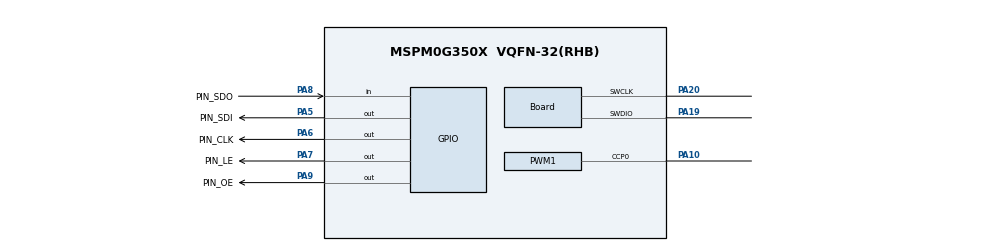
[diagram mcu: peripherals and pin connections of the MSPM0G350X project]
/**
 * @cliArgs --device "MSPM0G350X" --part "Default" --package "VQFN-32(RHB)" --product "mspm0_sdk@2.04.00.06"
 * @versions {"tool":"1.23.0+4000"}
 */

/**
 * Import the modules used in this configuration.
 */
const GPIO   = scripting.addModule("/ti/driverlib/GPIO", {}, false);
const GPIO1  = GPIO.addInstance();
const GPIO2  = GPIO.addInstance();
const GPIO3  = GPIO.addInstance();
const GPIO4  = GPIO.addInstance();
const GPIO5  = GPIO.addInstance();
const PWM    = scripting.addModule("/ti/driverlib/PWM", {}, false);
const PWM1   = PWM.addInstance();
const SYSCTL = scripting.addModule("/ti/driverlib/SYSCTL");

/**
 * Write custom configuration values to the imported modules.
 */
GPIO1.$name                         = "GPIO_SDI";
GPIO1.associatedPins[0].$name       = "PIN_SDI";
GPIO1.associatedPins[0].pin.$assign = "PA5";

const Board                       = scripting.addModule("/ti/driverlib/Board", {}, false);
Board.peripheral.$assign          = "DEBUGSS";
Board.peripheral.swclkPin.$assign = "PA20";
Board.peripheral.swdioPin.$assign = "PA19";

GPIO2.$name                         = "GPIO_CLK";
GPIO2.associatedPins[0].$name       = "PIN_CLK";
GPIO2.associatedPins[0].pin.$assign = "PA6";

GPIO3.$name                         = "GPIO_LE";
GPIO3.associatedPins[0].$name       = "PIN_LE";
GPIO3.associatedPins[0].pin.$assign = "PA7";

GPIO4.$name                         = "GPIO_SDO";
GPIO4.associatedPins[0].$name       = "PIN_SDO";
GPIO4.associatedPins[0].direction   = "INPUT";
GPIO4.associatedPins[0].pin.$assign = "PA8";

GPIO5.$name                         = "GPIO_OE";
GPIO5.associatedPins[0].$name       = "PIN_OE";
GPIO5.associatedPins[0].pin.$assign = "PA9";

PWM1.clockDivider                       = 8;
PWM1.clockPrescale                      = 20;
PWM1.timerCount                         = 2000;
PWM1.timerStartTimer                    = true;
PWM1.interrupts                         = ["LOAD_EVENT"];
PWM1.ccIndex                            = [0];
PWM1.$name                              = "PWM_1";
PWM1.PWM_CHANNEL_0.$name                = "ti_driverlib_pwm_PWMTimerCC0";
PWM1.PWM_CHANNEL_0.ccValue              = 1800;
PWM1.PWM_CHANNEL_0.dutyCycle            = 10;
PWM1.ccp0PinConfig.$name                = "ti_driverlib_gpio_GPIOPinGeneric0";
PWM1.ccp0PinConfig.direction            = scripting.forceWrite("OUTPUT");
PWM1.ccp0PinConfig.hideOutputInversion  = scripting.forceWrite(false);
PWM1.ccp0PinConfig.onlyInternalResistor = scripting.forceWrite(false);
PWM1.ccp0PinConfig.passedPeripheralType = scripting.forceWrite("Digital");
PWM1.peripheral.$assign                 = "TIMA1";
PWM1.peripheral.ccp0Pin.$assign         = "PA10";

SYSCTL.forceDefaultClkConfig = true;
SYSCTL.clockTreeEn           = true;

const ProjectConfig              = scripting.addModule("/ti/project_config/ProjectConfig", {}, false);
ProjectConfig.migrationCondition = true;
